/*
 * The MIT License (MIT)
 *
 * Copyright (c) 2015-2019 Erik Moqvist
 *
 * Permission is hereby granted, free of charge, to any person obtaining a copy
 * of this software and associated documentation files (the "Software"), to deal
 * in the Software without restriction, including without limitation the rights
 * to use, copy, modify, merge, publish, distribute, sublicense, and/or sell
 * copies of the Software, and to permit persons to whom the Software is
 * furnished to do so, subject to the following conditions:
 *
 * The above copyright notice and this permission notice shall be included in all
 * copies or substantial portions of the Software.
 *
 * THE SOFTWARE IS PROVIDED "AS IS", WITHOUT WARRANTY OF ANY KIND, EXPRESS OR
 * IMPLIED, INCLUDING BUT NOT LIMITED TO THE WARRANTIES OF MERCHANTABILITY,
 * FITNESS FOR A PARTICULAR PURPOSE AND NONINFRINGEMENT. IN NO EVENT SHALL THE
 * AUTHORS OR COPYRIGHT HOLDERS BE LIABLE FOR ANY CLAIM, DAMAGES OR OTHER
 * LIABILITY, WHETHER IN AN ACTION OF CONTRACT, TORT OR OTHERWISE, ARISING FROM,
 * OUT OF OR IN CONNECTION WITH THE SOFTWARE OR THE USE OR OTHER DEALINGS IN THE
 * SOFTWARE.
 */

VERSION ""

NS_ :

BS_:

BU_: DBG DRIVER IO MOTOR SENSOR

BO_ 100 DRIVER_HEARTBEAT: 1 DRIVER
 SG_ DRIVER_HEARTBEAT_cmd : 0|8@1+ (1,0) [0|0] ""  SENSOR,MOTOR

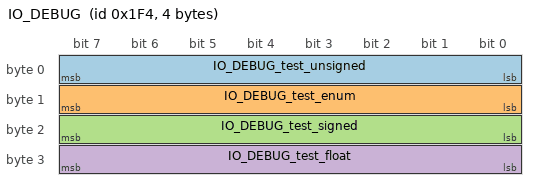
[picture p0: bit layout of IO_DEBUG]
BO_ 500 IO_DEBUG: 4 IO
 SG_ IO_DEBUG_test_unsigned : 0|8@1+ (1,0) [0|0] ""  DBG
 SG_ IO_DEBUG_test_enum : 8|8@1+ (1,0) [0|0] ""  DBG
 SG_ IO_DEBUG_test_signed : 16|8@1- (1,0) [0|0] ""  DBG
 SG_ IO_DEBUG_test_float : 24|8@1+ (0.5,0) [0|0] ""  DBG

BO_ 101 MOTOR_CMD: 1 DRIVER
 SG_ MOTOR_CMD_steer : 0|4@1- (1,-5) [-5|5] ""  MOTOR
 SG_ MOTOR_CMD_drive : 4|4@1+ (1,0) [0|9] ""  MOTOR

BO_ 400 MOTOR_STATUS: 3 MOTOR
 SG_ MOTOR_STATUS_wheel_error : 0|1@1+ (1,0) [0|0] ""  DRIVER,IO
 SG_ MOTOR_STATUS_speed_kph : 8|16@1+ (0.001,0) [0|0] "kph"  DRIVER,IO

BO_ 200 SENSOR_SONARS: 8 SENSOR
 SG_ SENSOR_SONARS_mux M : 0|4@1+ (1,0) [0|0] ""  DRIVER,IO
 SG_ SENSOR_SONARS_err_count : 4|12@1+ (1,0) [0|0] ""  DRIVER,IO
 SG_ SENSOR_SONARS_left m0 : 16|12@1+ (0.1,0) [0|0] ""  DRIVER,IO
 SG_ SENSOR_SONARS_middle m0 : 28|12@1+ (0.1,0) [0|0] ""  DRIVER,IO
 SG_ SENSOR_SONARS_right m0 : 40|12@1+ (0.1,0) [0|0] ""  DRIVER,IO
 SG_ SENSOR_SONARS_rear m0 : 52|12@1+ (0.1,0) [0|0] ""  DRIVER,IO
 SG_ SENSOR_SONARS_no_filt_left m1 : 16|12@1+ (0.1,0) [0|0] ""  DBG
 SG_ SENSOR_SONARS_no_filt_middle m1 : 28|12@1+ (0.1,0) [0|0] ""  DBG
 SG_ SENSOR_SONARS_no_filt_right m1 : 40|12@1+ (0.1,0) [0|0] ""  DBG
 SG_ SENSOR_SONARS_no_filt_rear m1 : 52|12@1+ (0.1,0) [0|0] ""  DBG

// Hello, as ds d.
// Foobar.
CM_ BU_ DRIVER "// The driver controller driving the car //"; // Comment. // In.
CM_ BU_ MOTOR "The motor controller of the car";
CM_ BU_ SENSOR "The sensor controller of the car";
CM_ BO_ 100 "Sync message used to synchronize the controllers";
BA_DEF_  "BusType" STRING ;
BA_DEF_ BO_  "GenMsgCycleTime" INT 0 0;
BA_DEF_ SG_  "FieldType" STRING ;
BA_DEF_DEF_  "BusType" "CAN";
BA_DEF_DEF_  "GenMsgCycleTime" 0;
BA_DEF_DEF_  "FieldType" "";
BA_ "GenMsgCycleTime" BO_ 100 1000;
BA_ "GenMsgCycleTime" BO_ 500 100;
BA_ "GenMsgCycleTime" BO_ 101 100;
BA_ "GenMsgCycleTime" BO_ 400 100;
BA_ "GenMsgCycleTime" BO_ 200 100;
BA_ "FieldType" SG_ 100 DRIVER_HEARTBEAT_cmd "DRIVER_HEARTBEAT_cmd";
BA_ "FieldType" SG_ 500 IO_DEBUG_test_enum "IO_DEBUG_test_enum";
VAL_ 100 DRIVER_HEARTBEAT_cmd 2 "DRIVER_HEARTBEAT_cmd_REBOOT" 1 "DRIVER_HEARTBEAT_cmd_SYNC" 0 "DRIVER_HEARTBEAT_cmd_NOOP" ;
VAL_ 500 IO_DEBUG_test_enum 2 "IO_DEBUG_test2_enum_two" 1 "IO_DEBUG_test2_enum_one" ;
